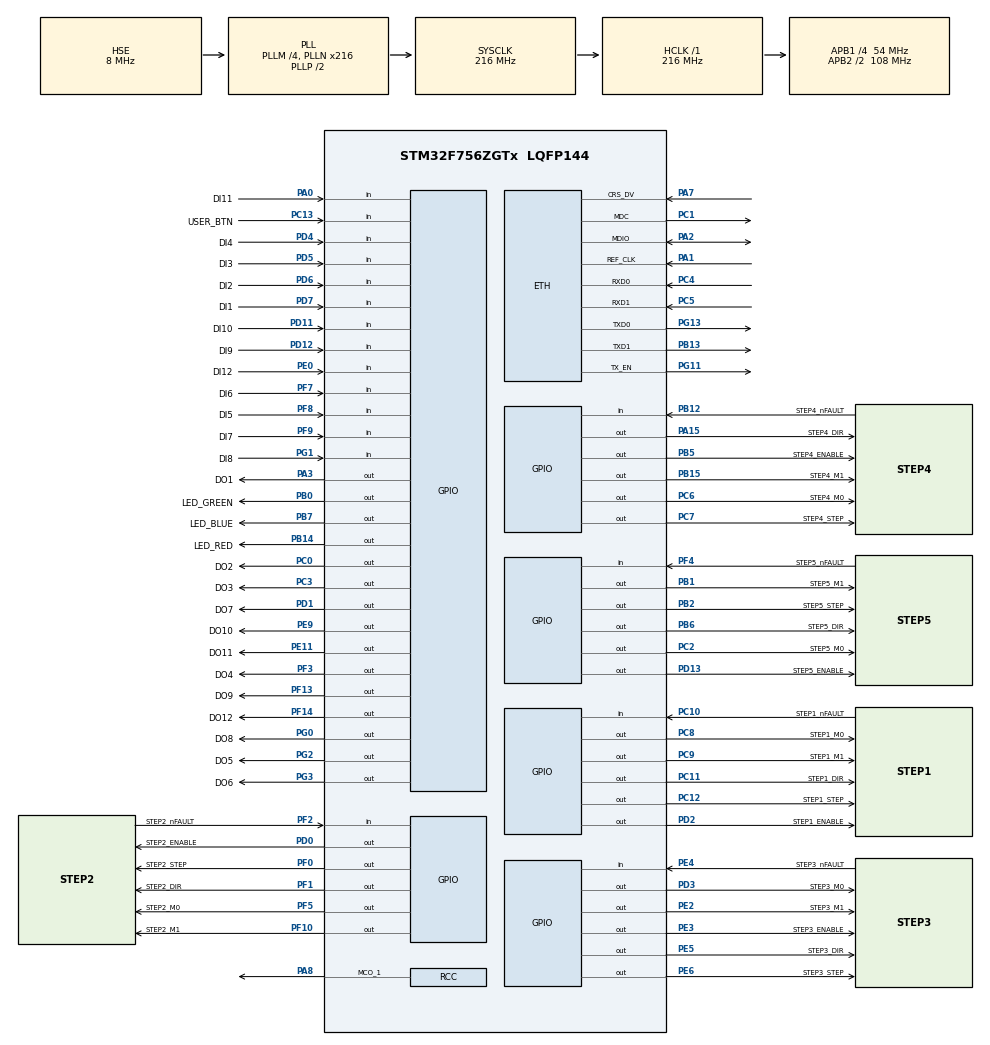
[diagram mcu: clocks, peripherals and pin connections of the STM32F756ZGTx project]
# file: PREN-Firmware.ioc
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CORTEX_M7.MPU_Control=__NULL
CORTEX_M7.default_mode_Activation=1
ETH.MediaInterface=HAL_ETH_RMII_MODE
LWIP.BSP.number=1
LWIP.IP_ADDRESS=010.000.001.001
LWIP.LWIP_DHCP=0
LWIP.LWIP_TCP=1
LWIP.MEM_SIZE=16*1024
LWIP.NETMASK_ADDRESS=255.255.255.000
LWIP.Version=v2.1.2_Cube
LWIP0.BSP.STBoard=false
LWIP0.BSP.api=BSP_COMPONENT_DRIVER
LWIP0.BSP.component=LAN8742
LWIP0.BSP.instance=LAN8742
LWIP0.BSP.name=Driver_PHY
LWIP0.BSP.semaphore=S_LAN8742
LWIP0.BSP.solution=LAN8742
Mcu.Family=STM32F7
Mcu.Name=STM32F756ZGTx
Mcu.Package=LQFP144
NVIC.PriorityGroup=NVIC_PRIORITYGROUP_4
NVIC.TIM8_BRK_TIM12_IRQn=true\:5\:0\:true\:false\:true\:true\:true\:true
PA0/WKUP.GPIO_Label=DI11
PA0/WKUP.Signal=GPIO_Input
PA1.Mode=RMII
PA1.Signal=ETH_REF_CLK
PA13.Mode=Serial_Wire
PA13.Signal=SYS_JTMS-SWDIO
PA14.Mode=Serial_Wire
PA14.Signal=SYS_JTCK-SWCLK
PA15.GPIO_Label=STEP4_DIR
PA15.Signal=GPIO_Output
PA2.Mode=RMII
PA2.Signal=ETH_MDIO
PA3.GPIO_Label=DO1
PA3.Signal=GPIO_Output
PA7.Mode=RMII
PA7.Signal=ETH_CRS_DV
PA8.Mode=Clock-out-1
PA8.Signal=RCC_MCO_1
PB0.GPIO_Label=LED_GREEN
PB0.Signal=GPIO_Output
PB1.GPIO_Label=STEP5_M1
PB1.Signal=GPIO_Output
PB12.GPIO_Label=STEP4_nFAULT
PB12.Signal=GPIO_Input
PB13.Mode=RMII
PB13.Signal=ETH_TXD1
PB14.GPIO_Label=LED_RED
PB14.Signal=GPIO_Output
PB15.GPIO_Label=STEP4_M1
PB15.Signal=GPIO_Output
PB2.GPIO_Label=STEP5_STEP
PB2.Signal=GPIO_Output
PB5.GPIO_Label=STEP4_ENABLE
PB5.Signal=GPIO_Output
PB6.GPIO_Label=STEP5_DIR
PB6.Signal=GPIO_Output
PB7.GPIO_Label=LED_BLUE
PB7.Signal=GPIO_Output
PC0.GPIO_Label=DO2
PC0.Signal=GPIO_Output
PC1.Mode=RMII
PC1.Signal=ETH_MDC
PC10.GPIO_Label=STEP1_nFAULT
PC10.Signal=GPIO_Input
PC11.GPIO_Label=STEP1_DIR
PC11.Signal=GPIO_Output
PC12.GPIO_Label=STEP1_STEP
PC12.Signal=GPIO_Output
PC13.GPIO_Label=USER_BTN
PC13.Signal=GPIO_Input
PC2.GPIO_Label=STEP5_M0
PC2.Signal=GPIO_Output
PC3.GPIO_Label=DO3
PC3.Signal=GPIO_Output
PC4.Mode=RMII
PC4.Signal=ETH_RXD0
PC5.Mode=RMII
PC5.Signal=ETH_RXD1
PC6.GPIO_Label=STEP4_M0
PC6.Signal=GPIO_Output
PC7.GPIO_Label=STEP4_STEP
PC7.Signal=GPIO_Output
PC8.GPIO_Label=STEP1_M0
PC8.Signal=GPIO_Output
PC9.GPIO_Label=STEP1_M1
PC9.Signal=GPIO_Output
PD0.GPIO_Label=STEP2_ENABLE
PD0.Signal=GPIO_Output
PD1.GPIO_Label=DO7
PD1.Signal=GPIO_Output
PD11.GPIO_Label=DI10
PD11.Signal=GPIO_Input
PD12.GPIO_Label=DI9
PD12.Signal=GPIO_Input
PD13.GPIO_Label=STEP5_ENABLE
PD13.Signal=GPIO_Output
PD2.GPIO_Label=STEP1_ENABLE
PD2.Signal=GPIO_Output
PD3.GPIO_Label=STEP3_M0
PD3.Signal=GPIO_Output
PD4.GPIO_Label=DI4
PD4.Signal=GPIO_Input
PD5.GPIO_Label=DI3
PD5.Signal=GPIO_Input
PD6.GPIO_Label=DI2
PD6.Signal=GPIO_Input
PD7.GPIO_Label=DI1
PD7.Signal=GPIO_Input
PE0.GPIO_Label=DI12
PE0.Signal=GPIO_Input
PE11.GPIO_Label=DO11
PE11.Signal=GPIO_Output
PE2.GPIO_Label=STEP3_M1
PE2.Signal=GPIO_Output
PE3.GPIO_Label=STEP3_ENABLE
PE3.Signal=GPIO_Output
PE4.GPIO_Label=STEP3_nFAULT
PE4.Signal=GPIO_Input
PE5.GPIO_Label=STEP3_DIR
PE5.Signal=GPIO_Output
PE6.GPIO_Label=STEP3_STEP
PE6.Signal=GPIO_Output
PE9.GPIO_Label=DO10
PE9.Signal=GPIO_Output
PF0.GPIO_Label=STEP2_STEP
PF0.Signal=GPIO_Output
PF1.GPIO_Label=STEP2_DIR
PF1.Signal=GPIO_Output
PF10.GPIO_Label=STEP2_M1
PF10.Signal=GPIO_Output
PF13.GPIO_Label=DO9
PF13.Signal=GPIO_Output
PF14.GPIO_Label=DO12
PF14.Signal=GPIO_Output
PF2.GPIO_Label=STEP2_nFAULT
PF2.Signal=GPIO_Input
PF3.GPIO_Label=DO4
PF3.Signal=GPIO_Output
PF4.GPIO_Label=STEP5_nFAULT
PF4.Signal=GPIO_Input
PF5.GPIO_Label=STEP2_M0
PF5.Signal=GPIO_Output
PF7.GPIO_Label=DI6
PF7.Signal=GPIO_Input
PF8.GPIO_Label=DI5
PF8.Signal=GPIO_Input
PF9.GPIO_Label=DI7
PF9.Signal=GPIO_Input
PG0.GPIO_Label=DO8
PG0.Signal=GPIO_Output
PG1.GPIO_Label=DI8
PG1.Signal=GPIO_Input
PG11.Mode=RMII
PG11.Signal=ETH_TX_EN
PG13.Mode=RMII
PG13.Signal=ETH_TXD0
PG2.GPIO_Label=DO5
PG2.Signal=GPIO_Output
PG3.GPIO_Label=DO6
PG3.Signal=GPIO_Output
PH0/OSC_IN.Mode=HSE-External-Clock-Source
PH0/OSC_IN.Signal=RCC_OSC_IN
PH1/OSC_OUT.Mode=HSE-External-Clock-Source
PH1/OSC_OUT.Signal=RCC_OSC_OUT
ProjectManager.HeapSize=0x200
ProjectManager.StackSize=0x400
ProjectManager.TargetToolchain=CMake
RCC.AHBFreq_Value=216000000
RCC.APB1CLKDivider=RCC_HCLK_DIV4
RCC.APB1Freq_Value=54000000
RCC.APB1TimFreq_Value=108000000
RCC.APB2CLKDivider=RCC_HCLK_DIV2
RCC.APB2Freq_Value=108000000
RCC.APB2TimFreq_Value=216000000
RCC.CortexFreq_Value=216000000
RCC.HCLKFreq_Value=216000000
RCC.HSE_VALUE=8000000
RCC.HSI_VALUE=16000000
RCC.LSE_VALUE=32768
RCC.PLLM=4
RCC.PLLN=216
RCC.PLLSourceVirtual=RCC_PLLSOURCE_HSE
RCC.RCC_MCO1Source=RCC_MCO1SOURCE_PLLCLK
RCC.RCC_MCODiv1=RCC_MCODIV_4
RCC.SYSCLKFreq_VALUE=216000000
RCC.SYSCLKSource=RCC_SYSCLKSOURCE_PLLCLK
RCC.USBFreq_Value=216000000
RCC.VCOOutputFreq_Value=432000000
TIM12.Period=2699
VP_LWIP_VS_Enabled.Mode=Enabled
VP_TIM12_VS_ClockSourceINT.Mode=Internal
board=custom

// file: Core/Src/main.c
/* USER CODE BEGIN Header */
/**
  ******************************************************************************
  * @file           : main.c
  * @brief          : Main program body
  ******************************************************************************
  * @attention
  *
  * Copyright (c) 2025 STMicroelectronics.
  * All rights reserved.
  *
  * This software is licensed under terms that can be found in the LICENSE file
  * in the root directory of this software component.
  * If no LICENSE file comes with this software, it is provided AS-IS.
  *
  ******************************************************************************
  */
/* USER CODE END Header */
#include "main.h"
#include "lwip.h"
#include "tim.h"
#include "gpio.h"

/* USER CODE BEGIN Includes */
#include "application.h"
/* USER CODE END Includes */

void SystemClock_Config(void);

int main(void)
{

  /* MCU Configuration--------------------------------------------------------*/

  /* Reset of all peripherals, Initializes the Flash interface and the Systick. */
  HAL_Init();

  /* USER CODE BEGIN Init */
  #ifdef DEBUG
  // Freeze TIM12 (APB1) and TIM8 (APB2) while the debugger halts the core
  DBGMCU->APB1FZ |= DBGMCU_APB1_FZ_DBG_TIM12_STOP;
  DBGMCU->APB2FZ |= DBGMCU_APB2_FZ_DBG_TIM8_STOP;
  #endif
  /* USER CODE END Init */

  /* Configure the system clock */
  SystemClock_Config();

  /* Initialize all configured peripherals */
  MX_GPIO_Init();
  MX_LWIP_Init();
  MX_TIM12_Init();
  /* USER CODE BEGIN 2 */
  HAL_TIM_Base_Start_IT(&htim12);

  application();  // contains super-loop

  /* USER CODE END 2 */

  /* Infinite loop */
  while (1)
  {

  }
}

void SystemClock_Config(void)
{
  RCC_OscInitTypeDef RCC_OscInitStruct = {0};
  RCC_ClkInitTypeDef RCC_ClkInitStruct = {0};

  /** Configure the main internal regulator output voltage
  */
  __HAL_RCC_PWR_CLK_ENABLE();
  __HAL_PWR_VOLTAGESCALING_CONFIG(PWR_REGULATOR_VOLTAGE_SCALE1);

  /** Initializes the RCC Oscillators according to the specified parameters
  * in the RCC_OscInitTypeDef structure.
  */
  RCC_OscInitStruct.OscillatorType = RCC_OSCILLATORTYPE_HSE;
  RCC_OscInitStruct.HSEState = RCC_HSE_BYPASS;
  RCC_OscInitStruct.PLL.PLLState = RCC_PLL_ON;
  RCC_OscInitStruct.PLL.PLLSource = RCC_PLLSOURCE_HSE;
  RCC_OscInitStruct.PLL.PLLM = 4;
  RCC_OscInitStruct.PLL.PLLN = 216;
  RCC_OscInitStruct.PLL.PLLP = RCC_PLLP_DIV2;
  RCC_OscInitStruct.PLL.PLLQ = 2;
  if (HAL_RCC_OscConfig(&RCC_OscInitStruct) != HAL_OK)
  {
    Error_Handler();
  }

  /** Activate the Over-Drive mode
  */
  if (HAL_PWREx_EnableOverDrive() != HAL_OK)
  {
    Error_Handler();
  }

  /** Initializes the CPU, AHB and APB buses clocks
  */
  RCC_ClkInitStruct.ClockType = RCC_CLOCKTYPE_HCLK|RCC_CLOCKTYPE_SYSCLK
                              |RCC_CLOCKTYPE_PCLK1|RCC_CLOCKTYPE_PCLK2;
  RCC_ClkInitStruct.SYSCLKSource = RCC_SYSCLKSOURCE_PLLCLK;
  RCC_ClkInitStruct.AHBCLKDivider = RCC_SYSCLK_DIV1;
  RCC_ClkInitStruct.APB1CLKDivider = RCC_HCLK_DIV4;
  RCC_ClkInitStruct.APB2CLKDivider = RCC_HCLK_DIV2;

  if (HAL_RCC_ClockConfig(&RCC_ClkInitStruct, FLASH_LATENCY_7) != HAL_OK)
  {
    Error_Handler();
  }
  HAL_RCC_MCOConfig(RCC_MCO1, RCC_MCO1SOURCE_PLLCLK, RCC_MCODIV_4);
}

void Error_Handler(void)
{
  __disable_irq();
  while (1)
  {
  }
}
